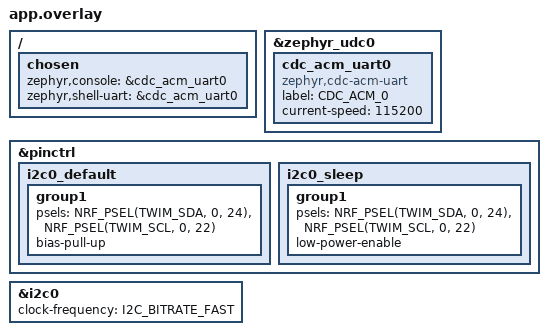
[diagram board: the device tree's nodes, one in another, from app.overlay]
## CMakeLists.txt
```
cmake_minimum_required(VERSION 3.20.0)

set(BOARD_ROOT ${CMAKE_SOURCE_DIR})
set(BOARD promicro_nrf52840/nrf52840)
set(DTC_OVERLAY_FILE "${CMAKE_SOURCE_DIR}/app.overlay")

find_package(Zephyr REQUIRED HINTS $ENV{ZEPHYR_BASE})
project(hello_world)

target_sources(app PRIVATE
    src/main.c
    src/transport.c
    src/ble.c
    src/imu.c
    src/gy85.c
)

target_include_directories(app PRIVATE src)
```

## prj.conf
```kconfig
CONFIG_USB_DEVICE_STACK=y
CONFIG_USB_DEVICE_PRODUCT="Hello World"
CONFIG_USB_DEVICE_PID=0x0001
CONFIG_USB_CDC_ACM=y
CONFIG_UART_INTERRUPT_DRIVEN=y
CONFIG_UART_LINE_CTRL=y
CONFIG_SERIAL=y
CONFIG_CONSOLE=y
CONFIG_UART_CONSOLE=y
CONFIG_USB_DEVICE_INITIALIZE_AT_BOOT=n
CONFIG_BUILD_OUTPUT_UF2=y
CONFIG_SHELL=y
CONFIG_KERNEL_SHELL=y
CONFIG_SHELL_BACKEND_SERIAL=y
CONFIG_REBOOT=y
CONFIG_CBPRINTF_FP_SUPPORT=y

CONFIG_I2C=y

# BLE
CONFIG_BT=y
CONFIG_BT_PERIPHERAL=y
CONFIG_BT_DEVICE_NAME="CR_IMU_BLE"
CONFIG_BT_DEVICE_APPEARANCE=0
CONFIG_BT_MAX_CONN=1
CONFIG_BT_GATT_DYNAMIC_DB=n

# MTU >= 39 for 36-byte payload; ACL TX buffers sized accordingly
CONFIG_BT_GATT_CLIENT=y
CONFIG_BT_L2CAP_TX_MTU=64
CONFIG_BT_BUF_ACL_TX_SIZE=72
CONFIG_BT_BUF_ACL_TX_COUNT=6
```

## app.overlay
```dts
/* ICM-45686 I2C mode. Wiring: DTQSYS SCL→P0.22, SDA→P0.24
 * QMC6309: via ICM-45686 internal I2C master (MREG over I2C)
 */

/ {
	chosen {
		zephyr,console = &cdc_acm_uart0;
		zephyr,shell-uart = &cdc_acm_uart0;
	};
};

&zephyr_udc0 {
	cdc_acm_uart0: cdc_acm_uart0 {
		compatible = "zephyr,cdc-acm-uart";
		label = "CDC_ACM_0";
		current-speed = <115200>;
	};
};

/* I2C0 pins with internal pull-ups for reliability */
&pinctrl {
	i2c0_default: i2c0_default {
		group1 {
			psels = <NRF_PSEL(TWIM_SDA, 0, 24)>,
					<NRF_PSEL(TWIM_SCL, 0, 22)>;
			bias-pull-up;
		};
	};
	i2c0_sleep: i2c0_sleep {
		group1 {
			psels = <NRF_PSEL(TWIM_SDA, 0, 24)>,
					<NRF_PSEL(TWIM_SCL, 0, 22)>;
			low-power-enable;
		};
	};
};

/* I2C0: TWIM, SDA=P0.24, SCL=P0.22, 400 kHz */
&i2c0 {
	status = "okay";
	clock-frequency = <I2C_BITRATE_FAST>;
};
```

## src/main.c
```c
#include <zephyr/kernel.h>
#include <zephyr/bluetooth/bluetooth.h>
#include <zephyr/bluetooth/gatt.h>
#include <zephyr/bluetooth/uuid.h>
#include <string.h>
#include "imu.h"
#include "transport.h"
#include "ble.h"

/* ── Частоты ─────────────────────────────────────────────────────────────── */
#define SAMPLE_HZ  100U   /* частота опроса датчика (должна совпадать с icm45686.c) */
#define BLE_HZ      25U   /* частота BLE-нотификаций                               */
#define LOG_HZ       1U   /* частота вывода в консоль (0 = выключить)              */

/*
 * GY-85 compatibility scaling — server pipeline expects ITG3200/ADXL345/HMC5883L counts:
 *   Gyro  (ITG3200):  14.375 LSB/°/s  → rad/s × (180/π) × 14.375 = × 823.4
 *   Accel (ADXL345):  256 LSB/g       → m/s² ÷ 9.81 × 256          = × 26.1
 *   Mag   (HMC5883L): 10.9 LSB/µT     → µT × 10.9
 *
 * Server pipeline: int16 / 100 / 0.14375 °/s → rad/s (gyro only; acc/mag are normalised).
 * 823.4 / 100 / 0.14375 × π/180 = 1.000 rad/s per rad/s ✓
 */
#define IMU_GYRO_SCALE   823.4f   /* rad/s  → ITG3200 counts */
#define IMU_ACCEL_SCALE   26.1f   /* m/s²   → ADXL345 counts */
#define IMU_MAG_SCALE     10.9f   /* µT     → HMC5883L counts */

/* IMU payload — 9 int16, 18 bytes. Fits in default ATT MTU=23 (max payload 20). */
typedef struct __attribute__((packed)) {
	int16_t gx, gy, gz;
	int16_t ax, ay, az;
	int16_t mx, my, mz;
} ImuPayload;

/* Service UUID:        eeb5483e-36e1-4688-b7f5-ea07361b26a8 */
/* Characteristic UUID: eeb5483e-36e1-4688-b7f5-ea07361b26a9 */
#define IMU_SVC_UUID_VAL \
	BT_UUID_128_ENCODE(0xeeb5483e, 0x36e1, 0x4688, 0xb7f5, 0xea07361b26a8)
#define IMU_CHR_UUID_VAL \
	BT_UUID_128_ENCODE(0xeeb5483e, 0x36e1, 0x4688, 0xb7f5, 0xea07361b26a9)

static struct bt_uuid_128 imu_svc_uuid = BT_UUID_INIT_128(IMU_SVC_UUID_VAL);
static struct bt_uuid_128 imu_chr_uuid = BT_UUID_INIT_128(IMU_CHR_UUID_VAL);

static ImuPayload imu_payload;

static void ccc_changed(const struct bt_gatt_attr *attr, uint16_t value)
{
	notify_enabled = (value == BT_GATT_CCC_NOTIFY);
	printk("Notify %s\n", notify_enabled ? "enabled" : "disabled");
}

BT_GATT_SERVICE_DEFINE(imu_svc,
	BT_GATT_PRIMARY_SERVICE(&imu_svc_uuid),
	BT_GATT_CHARACTERISTIC(&imu_chr_uuid.uuid,
		BT_GATT_CHRC_NOTIFY,
		BT_GATT_PERM_NONE,
		NULL, NULL, NULL),
	BT_GATT_CCC(ccc_changed, BT_GATT_PERM_READ | BT_GATT_PERM_WRITE),
);

static const struct bt_data ad[] = {
	BT_DATA_BYTES(BT_DATA_FLAGS, BT_LE_AD_GENERAL | BT_LE_AD_NO_BREDR),
	BT_DATA(BT_DATA_NAME_COMPLETE,
		CONFIG_BT_DEVICE_NAME,
		sizeof(CONFIG_BT_DEVICE_NAME) - 1),
};

static const struct bt_data sd[] = {
	BT_DATA_BYTES(BT_DATA_UUID128_ALL, IMU_SVC_UUID_VAL),
};

static void imu_log(const ImuPayload *data, uint32_t dt_us, uint32_t *cnt)
{
	if (LOG_HZ == 0 || ++(*cnt) < (SAMPLE_HZ / LOG_HZ)) {
		return;
	}
	*cnt = 0;
	uint32_t hz = (dt_us > 0) ? (1000000U / dt_us) : 0;
	printk("[dt=%uus ~%uHz] G:%.2f %.2f %.2f A:%.2f %.2f %.2f M:%.2f %.2f %.2f\n",
	       dt_us, hz,
	       (double)data->gx, (double)data->gy, (double)data->gz,
	       (double)data->ax, (double)data->ay, (double)data->az,
	       (double)data->mx, (double)data->my, (double)data->mz);
}

int main(void)
{
	int ret = transport_init();
	if (ret != 0) {
		while (1) { k_sleep(K_MSEC(1000)); }
	}

	ret = ble_init(ad, ARRAY_SIZE(ad), sd, ARRAY_SIZE(sd));
	if (ret != 0) {
		while (1) { k_sleep(K_MSEC(1000)); }
	}

	uint32_t log_cnt = 0;
	uint32_t notify_cnt = 0;
	uint32_t prev_ts_us = 0;

	while (1) {
		ImuData data;
		if (imu_get_data(&data)) {
			imu_payload.gx = (int16_t)(data.gx * IMU_GYRO_SCALE);
			imu_payload.gy = (int16_t)(data.gy * IMU_GYRO_SCALE);
			imu_payload.gz = (int16_t)(data.gz * IMU_GYRO_SCALE);
			imu_payload.ax = (int16_t)(data.ax * IMU_ACCEL_SCALE);
			imu_payload.ay = (int16_t)(data.ay * IMU_ACCEL_SCALE);
			imu_payload.az = (int16_t)(data.az * IMU_ACCEL_SCALE);
			imu_payload.mx = (int16_t)(data.mx * IMU_MAG_SCALE);
			imu_payload.my = (int16_t)(data.my * IMU_MAG_SCALE);
			imu_payload.mz = (int16_t)(data.mz * IMU_MAG_SCALE);

			uint32_t dt_us = (prev_ts_us != 0) ? (data.timestamp_us - prev_ts_us) : 0;
			prev_ts_us = data.timestamp_us;

			imu_log(&imu_payload, dt_us, &log_cnt);

			if (notify_enabled && (++notify_cnt % (SAMPLE_HZ / BLE_HZ)) == 0) {
				const struct bt_gatt_attr *attr = &imu_svc.attrs[2];
				bt_gatt_notify(current_conn, attr, &imu_payload, sizeof(imu_payload));
			}
		}
		k_sleep(K_MSEC(1000U / (SAMPLE_HZ * 5U)));
	}

	return 0;
}
```

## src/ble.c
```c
#include <zephyr/kernel.h>
#include <zephyr/bluetooth/bluetooth.h>
#include <zephyr/bluetooth/gatt.h>
#include "ble.h"

bool notify_enabled;
struct bt_conn *current_conn;

static const struct bt_data *adv_ad;
static size_t adv_ad_len;
static const struct bt_data *adv_sd;
static size_t adv_sd_len;

static struct k_work_delayable adv_work;
static struct k_work_delayable sub_watchdog;
static K_SEM_DEFINE(bt_ready_sem, 0, 1);

static void mtu_exchange_cb(struct bt_conn *conn, uint8_t err,
			     struct bt_gatt_exchange_params *params)
{
	printk("MTU exchange %s, MTU=%u\n",
	       err == 0 ? "OK" : "FAIL", bt_gatt_get_mtu(conn));
}
static struct bt_gatt_exchange_params mtu_params = { .func = mtu_exchange_cb };

static void adv_restart(void)
{
	bt_le_adv_stop();
	int ret = bt_le_adv_start(BT_LE_ADV_CONN, adv_ad, adv_ad_len, adv_sd, adv_sd_len);
	if (ret && ret != -EALREADY) {
		printk("BLE adv restart failed: %d, retrying...\n", ret);
		k_work_schedule(&adv_work, K_MSEC(500));
	} else {
		printk("BLE advertising restarted\n");
	}
}

static void adv_work_handler(struct k_work *work)
{
	adv_restart();
}

/* Periodic check: if connected but server is not subscribed to notifications,
 * the Python app likely died (BlueZ resets the CCC when the DBus owner dies).
 * Disconnect so advertising restarts and the new server session can connect. */
static void sub_watchdog_handler(struct k_work *work)
{
	if (!current_conn) {
		return;
	}
	if (!notify_enabled) {
		printk("BLE: no GATT subscription — dropping stale connection\n");
		bt_conn_disconnect(current_conn, BT_HCI_ERR_REMOTE_USER_TERM_CONN);
	} else {
		k_work_schedule(&sub_watchdog, K_SECONDS(5));
	}
}

static void adv_watchdog_thread(void *p1, void *p2, void *p3)
{
	k_sem_take(&bt_ready_sem, K_FOREVER);
	while (1) {
		k_sleep(K_SECONDS(3));
		if (current_conn != NULL) {
			continue;
		}
		printk("watchdog: forcing adv restart\n");
		adv_restart();
	}
}

K_THREAD_DEFINE(watchdog_tid, 1024, adv_watchdog_thread, NULL, NULL, NULL, 7, 0, 0);

static void connected(struct bt_conn *conn, uint8_t err)
{
	if (err) {
		printk("BLE connect failed: %d\n", err);
		return;
	}
	current_conn = bt_conn_ref(conn);
	printk("BLE connected, MTU=%u\n", bt_gatt_get_mtu(conn));

	k_work_schedule(&sub_watchdog, K_SECONDS(5));

	bt_gatt_exchange_mtu(conn, &mtu_params);

	/* 10–20 ms connection interval, 1 s supervision timeout */
	static const struct bt_le_conn_param param = {
		.interval_min = 8,   /* 8 × 1.25 ms = 10 ms */
		.interval_max = 16,  /* 16 × 1.25 ms = 20 ms */
		.latency = 0,
		.timeout = 100,      /* 100 × 10 ms = 1 s */
	};
	bt_conn_le_param_update(conn, &param);
}

static void disconnected(struct bt_conn *conn, uint8_t reason)
{
	printk("BLE disconnected: %d\n", reason);
	notify_enabled = false;
	k_work_cancel_delayable(&sub_watchdog);
	bt_conn_unref(current_conn);
	current_conn = NULL;
	k_work_schedule(&adv_work, K_MSEC(100));
}

BT_CONN_CB_DEFINE(conn_callbacks) = {
	.connected    = connected,
	.disconnected = disconnected,
};

int ble_init(const struct bt_data *ad, size_t ad_len,
             const struct bt_data *sd, size_t sd_len)
{
	adv_ad     = ad;
	adv_ad_len = ad_len;
	adv_sd     = sd;
	adv_sd_len = sd_len;

	k_work_init_delayable(&adv_work, adv_work_handler);
	k_work_init_delayable(&sub_watchdog, sub_watchdog_handler);

	int ret = bt_enable(NULL);
	if (ret != 0) {
		printk("BLE init failed: %d\n", ret);
		return ret;
	}

	ret = bt_le_adv_start(BT_LE_ADV_CONN, ad, ad_len, sd, sd_len);
	if (ret != 0) {
		printk("BLE adv failed: %d\n", ret);
		return ret;
	}

	printk("BLE advertising as \"%s\"\n", CONFIG_BT_DEVICE_NAME);
	k_sem_give(&bt_ready_sem);
	return 0;
}
```

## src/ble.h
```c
#ifndef BLE_H
#define BLE_H

#include <stdbool.h>
#include <zephyr/bluetooth/bluetooth.h>
#include <zephyr/bluetooth/conn.h>

extern bool notify_enabled;
extern struct bt_conn *current_conn;

int ble_init(const struct bt_data *ad, size_t ad_len,
             const struct bt_data *sd, size_t sd_len);

#endif /* BLE_H */
```

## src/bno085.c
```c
#include "bno085.h"
#include "bno085_hal.h"
#include "imu.h"
#include "imu_driver.h"
#include "sh2/sh2.h"
#include "sh2/sh2_SensorValue.h"
#include "sh2/sh2_err.h"
#include <zephyr/kernel.h>
#include <zephyr/init.h>
#include <string.h>

static ImuData latest;
static bool data_ready;
static K_MUTEX_DEFINE(bno085_mutex);

static void sensor_cb(void *cookie, sh2_SensorEvent_t *event)
{
	sh2_SensorValue_t val;
	if (sh2_decodeSensorEvent(&val, event) != SH2_OK) {
		return;
	}

	k_mutex_lock(&bno085_mutex, K_FOREVER);
	switch (val.sensorId) {
	case SH2_GYROSCOPE_CALIBRATED:
		latest.gx = val.un.gyroscope.x;
		latest.gy = val.un.gyroscope.y;
		latest.gz = val.un.gyroscope.z;
		break;
	case SH2_ACCELEROMETER:
		latest.ax = val.un.accelerometer.x;
		latest.ay = val.un.accelerometer.y;
		latest.az = val.un.accelerometer.z;
		latest.timestamp_us = (uint32_t)(k_uptime_get() * 1000U);
		data_ready = true;
		break;
	case SH2_MAGNETIC_FIELD_CALIBRATED:
		latest.mx = val.un.magneticField.x;
		latest.my = val.un.magneticField.y;
		latest.mz = val.un.magneticField.z;
		break;
	}
	k_mutex_unlock(&bno085_mutex);
}

static void configure_sensors(void)
{
	sh2_SensorConfig_t cfg = {0};
	cfg.reportInterval_us = 1000000U / IMU_SAMPLE_HZ;
	sh2_setSensorConfig(SH2_GYROSCOPE_CALIBRATED, &cfg);
	sh2_setSensorConfig(SH2_ACCELEROMETER,        &cfg);
	cfg.reportInterval_us = MAX(1000000U / IMU_SAMPLE_HZ, 10000U);
	sh2_setSensorConfig(SH2_MAGNETIC_FIELD_CALIBRATED, &cfg);
	printk("BNO085: gyro/accel %uHz, mag %uHz\n",
	       IMU_SAMPLE_HZ, 1000000U / cfg.reportInterval_us);
}

static void event_cb(void *cookie, sh2_AsyncEvent_t *event)
{
	if (event->eventId == SH2_RESET) {
		printk("BNO085: reset — reconfiguring sensors\n");
		configure_sensors();
	}
}

static void bno085_thread(void *p1, void *p2, void *p3)
{
	k_sleep(K_SECONDS(5));
	printk("BNO085: thread started, opening...\n");
	int ret = sh2_open(&bno085_hal, event_cb, NULL);
	if (ret != SH2_OK) {
		printk("BNO085: sh2_open failed: %d\n", ret);
		return;
	}
	printk("BNO085: sh2_open OK\n");

	sh2_setSensorCallback(sensor_cb, NULL);

	k_sleep(K_MSEC(100));

	configure_sensors();

	while (1) {
		sh2_service();
		k_yield();
	}
}

K_THREAD_DEFINE(bno085_tid, 4096, bno085_thread, NULL, NULL, NULL, 5, 0, 0);

static bool bno085_get_data(ImuData *out)
{
	k_mutex_lock(&bno085_mutex, K_FOREVER);
	bool ready = data_ready;
	if (ready) {
		*out = latest;
		data_ready = false;
	}
	k_mutex_unlock(&bno085_mutex);
	return ready;
}

static const ImuDriverOps bno085_driver = {
	.init     = NULL,
	.get_data = bno085_get_data,
};

static int bno085_register(void)
{
	imu_register_driver(&bno085_driver);
	return 0;
}

SYS_INIT(bno085_register, APPLICATION, CONFIG_APPLICATION_INIT_PRIORITY);
```

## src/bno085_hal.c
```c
#include "bno085_hal.h"
#include <zephyr/kernel.h>
#include <zephyr/drivers/i2c.h>
#include <string.h>

#define BNO085_ADDR 0x4B

static const struct device *i2c_dev;

static int bno_open(sh2_Hal_t *self)
{
    i2c_dev = DEVICE_DT_GET(DT_NODELABEL(i2c0));
    if (!device_is_ready(i2c_dev)) {
        printk("BNO085: i2c0 not ready\n");
        return -1;
    }

    k_sleep(K_MSEC(300));
    return 0;
}

static void bno_close(sh2_Hal_t *self)
{
    i2c_dev = NULL;
}

static int bno_read(sh2_Hal_t *self, uint8_t *pBuffer, unsigned len, uint32_t *t_us)
{
    /* First read: 4-byte header to get packet length */
    uint8_t hdr[4];
    if (i2c_read(i2c_dev, hdr, sizeof(hdr), BNO085_ADDR) != 0) {
        return 0;
    }

    uint16_t pkt_len = ((uint16_t)hdr[1] << 8) | hdr[0];
    pkt_len &= 0x7FFF; /* strip continuation bit */

    if (pkt_len < 4 || pkt_len > len) {
        return 0;
    }

    /* Second read: BNO085 resets its pointer at each I2C START condition,
     * so we must read the full packet (header + payload) from the beginning */
    if (i2c_read(i2c_dev, pBuffer, pkt_len, BNO085_ADDR) != 0) {
        return 0;
    }

    *t_us = (uint32_t)(k_uptime_get() * 1000U);
    return pkt_len;
}

static int bno_write(sh2_Hal_t *self, uint8_t *pBuffer, unsigned len)
{
    int ret = i2c_write(i2c_dev, pBuffer, len, BNO085_ADDR);
    if (ret != 0) {
        return -1; /* SHTP: -1 = abort, 0 = retry, >0 = success */
    }
    return len;
}

static uint32_t bno_get_time_us(sh2_Hal_t *self)
{
    return (uint32_t)(k_uptime_get() * 1000U);
}

sh2_Hal_t bno085_hal = {
    .open      = bno_open,
    .close     = bno_close,
    .read      = bno_read,
    .write     = bno_write,
    .getTimeUs = bno_get_time_us,
};
```

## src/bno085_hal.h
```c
#pragma once
#include "sh2/sh2_hal.h"

extern sh2_Hal_t bno085_hal;
```

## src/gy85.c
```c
#include "imu.h"
#include "imu_driver.h"

#include <zephyr/kernel.h>
#include <zephyr/init.h>
#include <zephyr/drivers/i2c.h>
#include <zephyr/sys/printk.h>
#include <stdbool.h>
#include <stdint.h>
#include <stdlib.h>

/* ── ITG3200 gyroscope ───────────────────────────────────────────────────── */
#define ITG_ADDR       0x68u
#define ITG_WHO_AM_I   0x00u
#define ITG_SMPLRT_DIV 0x15u
#define ITG_DLPF_FS    0x16u
#define ITG_PWR_MGM    0x3Eu
#define ITG_TEMP_H     0x1Bu  /* TEMP_H TEMP_L GX_H GX_L GY_H GY_L GZ_H GZ_L */
/* FS_SEL=3 → 14.375 LSB/°/s; to rad/s: raw × π/(14.375×180) */
#define ITG_SCALE      (3.14159265f / (14.375f * 180.0f))

/* ── ADXL345 accelerometer ───────────────────────────────────────────────── */
#define ADXL_ADDR      0x53u  /* SDO=GND on standard GY-85; use 0x1D if SDO=3V3 */
#define ADXL_DEVID     0x00u
#define ADXL_BW_RATE   0x2Cu
#define ADXL_PWR_CTL   0x2Du
#define ADXL_FORMAT    0x31u
#define ADXL_DATAX0    0x32u
/* ±2g, 256 LSB/g; to m/s²: raw × 9.81/256 */
#define ADXL_SCALE     (9.81f / 256.0f)

/* ── HMC5883L magnetometer ───────────────────────────────────────────────── */
#define HMC_ADDR       0x1Eu
#define HMC_CFG_A      0x00u
#define HMC_CFG_B      0x01u
#define HMC_MODE       0x02u
#define HMC_DATA_H     0x03u  /* X_H X_L Z_H Z_L Y_H Y_L (Z before Y!) */
#define HMC_STATUS     0x09u
#define HMC_IDA        0x0Au  /* 'H' = 0x48 */
/* gain=1 (Config B=0x20) → 1090 LSB/Ga = 10.9 LSB/µT; to µT: raw/10.9 */
#define HMC_SCALE      (1.0f / 10.9f)
#define HMC_POLL_MS    14u    /* 75 Hz output → poll every ~13 ms */

static const struct device *i2c_dev;

static inline int rd(uint8_t addr, uint8_t reg, uint8_t *buf, uint8_t len)
{
	return i2c_burst_read(i2c_dev, addr, reg, buf, len);
}

static inline int wr(uint8_t addr, uint8_t reg, uint8_t val)
{
	return i2c_reg_write_byte(i2c_dev, addr, reg, val);
}

/* ── ITG3200 ─────────────────────────────────────────────────────────────── */
static bool itg3200_init(void)
{
	uint8_t id = 0;
	if (rd(ITG_ADDR, ITG_WHO_AM_I, &id, 1) != 0) {
		printk("ITG3200: no ACK at 0x%02X\n", ITG_ADDR);
		return false;
	}
	/* WHO_AM_I bits[6:1] = fixed 110100; bit0 = AD0. Expect 0x68 or 0x69 */
	if (id != 0x68 && id != 0x69) {
		printk("ITG3200 WHO_AM_I=0x%02X unexpected\n", id);
		return false;
	}
	printk("ITG3200 WHO_AM_I=0x%02X OK\n", id);

	wr(ITG_ADDR, ITG_PWR_MGM, 0x80);  /* reset */
	k_sleep(K_MSEC(10));
	wr(ITG_ADDR, ITG_DLPF_FS, 0x19);  /* FS_SEL=3 (±2000°/s), DLPF=1 (188Hz BW) */
	wr(ITG_ADDR, ITG_SMPLRT_DIV, 9);  /* 1kHz / 10 = 100Hz sample rate */
	wr(ITG_ADDR, ITG_PWR_MGM, 0x01);  /* PLL with X gyro clock */
	k_sleep(K_MSEC(50));
	return true;
}

static bool itg3200_read(float *gx, float *gy, float *gz)
{
	uint8_t buf[8];
	if (rd(ITG_ADDR, ITG_TEMP_H, buf, 8) != 0) return false;
	/* big-endian: [TEMP_H TEMP_L GX_H GX_L GY_H GY_L GZ_H GZ_L] */
	int16_t rx = (int16_t)((buf[2] << 8) | buf[3]);
	int16_t ry = (int16_t)((buf[4] << 8) | buf[5]);
	int16_t rz = (int16_t)((buf[6] << 8) | buf[7]);
	*gx = rx * ITG_SCALE;
	*gy = ry * ITG_SCALE;
	*gz = rz * ITG_SCALE;
	return true;
}

/* ── ADXL345 ─────────────────────────────────────────────────────────────── */
static bool adxl345_init(void)
{
	uint8_t id = 0;
	if (rd(ADXL_ADDR, ADXL_DEVID, &id, 1) != 0) {
		printk("ADXL345: no ACK at 0x%02X\n", ADXL_ADDR);
		return false;
	}
	if (id != 0xE5) {
		printk("ADXL345 DEVID=0x%02X unexpected (expect 0xE5)\n", id);
		return false;
	}
	printk("ADXL345 DEVID=0xE5 OK\n");

	wr(ADXL_ADDR, ADXL_FORMAT,  0x00);  /* ±2g, right-justified 10-bit */
	wr(ADXL_ADDR, ADXL_BW_RATE, 0x0A); /* 100Hz output */
	wr(ADXL_ADDR, ADXL_PWR_CTL, 0x08); /* measure mode */
	k_sleep(K_MSEC(10));
	return true;
}

static bool adxl345_read(float *ax, float *ay, float *az)
{
	uint8_t buf[6];
	if (rd(ADXL_ADDR, ADXL_DATAX0, buf, 6) != 0) return false;
	/* little-endian: [X0 X1 Y0 Y1 Z0 Z1] */
	int16_t rx = (int16_t)((buf[1] << 8) | buf[0]);
	int16_t ry = (int16_t)((buf[3] << 8) | buf[2]);
	int16_t rz = (int16_t)((buf[5] << 8) | buf[4]);
	*ax = rx * ADXL_SCALE;
	*ay = ry * ADXL_SCALE;
	*az = rz * ADXL_SCALE;
	return true;
}

/* ── HMC5883L ────────────────────────────────────────────────────────────── */
static float hmc_last[3] = {0};
static uint32_t hmc_next_ms = 0;

static bool hmc5883l_init(void)
{
	uint8_t id = 0;
	if (rd(HMC_ADDR, HMC_IDA, &id, 1) != 0) {
		printk("HMC5883L: no ACK at 0x%02X\n", HMC_ADDR);
		return false;
	}
	if (id != 0x48) {  /* 'H' */
		printk("HMC5883L IDA=0x%02X unexpected (expect 0x48)\n", id);
		return false;
	}
	printk("HMC5883L IDA=0x48 OK\n");

	wr(HMC_ADDR, HMC_CFG_A, 0x18);  /* 1-sample avg, 75Hz output rate */
	wr(HMC_ADDR, HMC_CFG_B, 0x20);  /* gain=1: ±1.3 Ga, 1090 LSB/Ga */
	wr(HMC_ADDR, HMC_MODE,  0x00);  /* continuous measurement mode */
	k_sleep(K_MSEC(10));
	return true;
}

static void hmc5883l_update(float *mx, float *my, float *mz)
{
	uint32_t now = k_uptime_get_32();
	if ((int32_t)(now - hmc_next_ms) < 0) {
		*mx = hmc_last[0]; *my = hmc_last[1]; *mz = hmc_last[2];
		return;
	}
	hmc_next_ms = now + HMC_POLL_MS;

	uint8_t st = 0;
	if (rd(HMC_ADDR, HMC_STATUS, &st, 1) != 0 || !(st & 0x01)) {
		*mx = hmc_last[0]; *my = hmc_last[1]; *mz = hmc_last[2];
		return;
	}

	uint8_t buf[6];
	if (rd(HMC_ADDR, HMC_DATA_H, buf, 6) != 0) {
		*mx = hmc_last[0]; *my = hmc_last[1]; *mz = hmc_last[2];
		return;
	}

	/* big-endian: [X_H X_L Z_H Z_L Y_H Y_L] — Z before Y is correct per datasheet */
	int16_t rx = (int16_t)((buf[0] << 8) | buf[1]);
	int16_t rz = (int16_t)((buf[2] << 8) | buf[3]);
	int16_t ry = (int16_t)((buf[4] << 8) | buf[5]);

	/* ±4096 = overflow sentinel */
	if (rx == -4096 || ry == -4096 || rz == -4096) {
		*mx = hmc_last[0]; *my = hmc_last[1]; *mz = hmc_last[2];
		return;
	}

	hmc_last[0] = rx * HMC_SCALE;
	hmc_last[1] = ry * HMC_SCALE;
	hmc_last[2] = rz * HMC_SCALE;
	*mx = hmc_last[0]; *my = hmc_last[1]; *mz = hmc_last[2];
}

/* ── Sensor thread ───────────────────────────────────────────────────────── */
static ImuData latest = {0};
static bool data_ready = false;
static K_MUTEX_DEFINE(gy85_mutex);

static void gy85_thread(void *p1, void *p2, void *p3)
{
	ARG_UNUSED(p1); ARG_UNUSED(p2); ARG_UNUSED(p3);

	k_sleep(K_MSEC(4000));

	i2c_dev = DEVICE_DT_GET(DT_NODELABEL(i2c0));
	if (!device_is_ready(i2c_dev)) {
		printk("I2C0 not ready! Check app.overlay\n");
		return;
	}

	bool itg_ok = false, adxl_ok = false, hmc_ok = false;
	for (int attempt = 1; !(itg_ok && adxl_ok); attempt++) {
		itg_ok  = itg3200_init();
		adxl_ok = adxl345_init();
		if (!(itg_ok && adxl_ok)) {
			printk("GY-85 init fail (attempt %d), retry in 2s\n", attempt);
			k_sleep(K_MSEC(2000));
		}
	}
	hmc_ok = hmc5883l_init();
	printk("GY-85 ready: ITG=%d ADXL=%d HMC=%d\n", itg_ok, adxl_ok, hmc_ok);

	int64_t next_tick = k_uptime_get() + 10;

	while (1) {
		float gx, gy, gz, ax, ay, az, mx = 0, my = 0, mz = 0;

		bool ok = itg3200_read(&gx, &gy, &gz) && adxl345_read(&ax, &ay, &az);
		if (hmc_ok) hmc5883l_update(&mx, &my, &mz);

		if (ok) {
			k_mutex_lock(&gy85_mutex, K_FOREVER);
			latest.gx = gx; latest.gy = gy; latest.gz = gz;
			latest.ax = ax; latest.ay = ay; latest.az = az;
			latest.mx = mx; latest.my = my; latest.mz = mz;
			latest.timestamp_us = (uint32_t)(k_uptime_get() * 1000U);
			data_ready = true;
			k_mutex_unlock(&gy85_mutex);
		}

		int64_t delay = next_tick - k_uptime_get();
		if (delay > 0) k_sleep(K_MSEC((int32_t)delay));
		next_tick += 10;
	}
}

K_THREAD_DEFINE(gy85_tid, 2048, gy85_thread, NULL, NULL, NULL, 5, 0, 0);

/* ── IMU driver registration ─────────────────────────────────────────────── */
static bool gy85_get_data(ImuData *out)
{
	k_mutex_lock(&gy85_mutex, K_FOREVER);
	bool ready = data_ready;
	if (ready) {
		*out = latest;
		data_ready = false;
	}
	k_mutex_unlock(&gy85_mutex);
	return ready;
}

static const ImuDriverOps gy85_driver = {
	.init     = NULL,
	.get_data = gy85_get_data,
};

static int gy85_register(void)
{
	imu_register_driver(&gy85_driver);
	return 0;
}

SYS_INIT(gy85_register, APPLICATION, CONFIG_APPLICATION_INIT_PRIORITY);
```

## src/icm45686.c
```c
#include "imu.h"
#include "imu_driver.h"

#include <zephyr/kernel.h>
#include <zephyr/init.h>
#include <zephyr/drivers/i2c.h>
#include <zephyr/sys/printk.h>
#include <zephyr/sys/util.h>

#include <string.h>
#include <errno.h>
#include <stdbool.h>
#include <stdint.h>
#include <stdlib.h>
#include <math.h>

/* ==================== ICM-45686 registers ==================== */
#define ICM_REG_ACCEL_X0     0x00
#define ICM_REG_PWR_MGMT0    0x10
#define ICM_REG_ACCEL_CFG0   0x1B
#define ICM_REG_GYRO_CFG0    0x1C
#define ICM_REG_WHO_AM_I     0x72
#define ICM_WHO_AM_I_VAL     0xE9

#define ICM_PWR_LN           0x0F
/* ICM-45686 FS_SEL bits are at [7:4], ODR at [3:0].
 * ACCEL_CONFIG0: 0000=±32g 0001=±16g 0010=±8g 0011=±4g 0100=±2g
 * GYRO_CONFIG0:  0000=±4000dps 0001=±2000dps 0010=±1000dps ... */
#define ICM_ACCEL_CFG_VAL    (0x40 | 0x09)   /* bits[7:4]=0100 → ±2g,     ODR=200 Hz */
#define ICM_GYRO_CFG_VAL     (0x10 | 0x09)   /* bits[7:4]=0001 → ±2000dps, ODR=200 Hz */

#define ICM_ACCEL_SCALE      (2.0f * 9.81f / 32768.0f)   /* ±2g */
#define ICM_GYRO_SCALE       (2000.0f * 3.14159265f / (180.0f * 32768.0f))   /* ±2000dps */

/* I2C addresses: AP_AD0=0 → 0x68, AP_AD0=1 → 0x69 */
#define ICM_ADDR_0           0x68u
#define ICM_ADDR_1           0x69u

/* MREG (indirect register) access */
#define ICM_IREG_ADDR_H      0x7Cu
#define ICM_IREG_DATA        0x7Eu

static const struct device *i2c_dev;
static uint8_t icm_addr;
static K_MUTEX_DEFINE(icm_bus_mutex);

/* Gyro zero-rate offset measured at startup (rad/s). */
static float gyro_bias[3] = {0};

/* ==================== I2C low-level ==================== */
static int icm_read(uint8_t reg, uint8_t *buf, uint8_t len)
{
	return i2c_burst_read(i2c_dev, icm_addr, reg, buf, len);
}

static int icm_write(uint8_t reg, uint8_t val)
{
	return i2c_reg_write_byte(i2c_dev, icm_addr, reg, val);
}

/* ==================== MREG (indirect) access ==================== */
/* Writes addr_h, addr_l, val to IREG_ADDR_H/L/DATA in one burst */
static int icm_mreg_write_nolock(uint16_t addr, uint8_t val)
{
	uint8_t tx[3] = { addr >> 8, addr & 0xFF, val };
	return i2c_burst_write(i2c_dev, icm_addr, ICM_IREG_ADDR_H, tx, 3);
}

/* Sets IREG address, waits briefly, reads IREG_DATA */
static int icm_mreg_read_nolock(uint16_t addr, uint8_t *val)
{
	uint8_t tx[2] = { addr >> 8, addr & 0xFF };
	int rc = i2c_burst_write(i2c_dev, icm_addr, ICM_IREG_ADDR_H, tx, 2);
	if (rc) return rc;
	k_busy_wait(50);
	return i2c_reg_read_byte(i2c_dev, icm_addr, ICM_IREG_DATA, val);
}

/* ==================== I2CM master registers ==================== */
#define I2CM_COMMAND_0       0xa206u
#define I2CM_DEV_PROFILE0    0xa20eu
#define I2CM_DEV_PROFILE1    0xa20fu
#define I2CM_CONTROL         0xa216u
#define I2CM_STATUS          0xa218u
#define I2CM_EXT_DEV_STATUS  0xa21au
#define I2CM_RD_DATA0        0xa21bu
#define I2CM_WR_DATA0        0xa233u

#define I2CM_CTRL_WRITE      (0x08u | 0x01u)
#define I2CM_CTRL_READ       (0x40u | 0x08u | 0x01u)

static void icm_i2cm_reset_nolock(void)
{
	uint8_t dummy;
	icm_mreg_read_nolock(I2CM_STATUS, &dummy);
	icm_mreg_read_nolock(I2CM_EXT_DEV_STATUS, &dummy);
}

static int icm_i2cm_wait_nolock(void)
{
	uint8_t st = 0;
	for (int i = 0; i < 18; i++) {
		if (icm_mreg_read_nolock(I2CM_STATUS, &st) != 0) return -EIO;
		if ((st & 0x02) && !(st & 0x01)) {
			return (st & 0x3C) ? -EIO : 0;
		}
		k_busy_wait(100);
	}
	return -ETIMEDOUT;
}

static int icm_i2cm_read_reg(uint8_t addr, uint8_t reg, uint8_t *val)
{
	k_mutex_lock(&icm_bus_mutex, K_FOREVER);
	icm_i2cm_reset_nolock();
	int rc = 0;
	rc |= icm_mreg_write_nolock(I2CM_DEV_PROFILE0, reg);
	rc |= icm_mreg_write_nolock(I2CM_DEV_PROFILE1, addr);
	rc |= icm_mreg_write_nolock(I2CM_COMMAND_0, 0x91);
	rc |= icm_mreg_write_nolock(I2CM_CONTROL, I2CM_CTRL_READ);
	if (rc == 0 && icm_i2cm_wait_nolock() == 0) {
		uint8_t dev_st;
		icm_mreg_read_nolock(I2CM_EXT_DEV_STATUS, &dev_st);
		if (!(dev_st & 0x01))
			rc = icm_mreg_read_nolock(I2CM_RD_DATA0, val);
		else
			rc = -EIO;
	}
	k_mutex_unlock(&icm_bus_mutex);
	return rc;
}

static int icm_i2cm_read_bytes(uint8_t addr, uint8_t reg, uint8_t *buf, uint8_t len)
{
	if (len == 0 || len > 15) return -EINVAL;
	k_mutex_lock(&icm_bus_mutex, K_FOREVER);
	icm_i2cm_reset_nolock();
	int rc = 0;
	rc |= icm_mreg_write_nolock(I2CM_DEV_PROFILE0, reg);
	rc |= icm_mreg_write_nolock(I2CM_DEV_PROFILE1, addr);
	rc |= icm_mreg_write_nolock(I2CM_COMMAND_0, 0x90 | (len & 0x0F));
	rc |= icm_mreg_write_nolock(I2CM_CONTROL, I2CM_CTRL_READ);
	if (rc == 0 && icm_i2cm_wait_nolock() == 0) {
		uint8_t dev_st;
		icm_mreg_read_nolock(I2CM_EXT_DEV_STATUS, &dev_st);
		if (!(dev_st & 0x01)) {
			for (int i = 0; i < len; i++) {
				if (icm_mreg_read_nolock(I2CM_RD_DATA0 + i, &buf[i]) != 0) {
					rc = -EIO;
					break;
				}
			}
		} else rc = -EIO;
	}
	k_mutex_unlock(&icm_bus_mutex);
	return rc;
}

static int icm_i2cm_write_reg(uint8_t addr, uint8_t reg, uint8_t val)
{
	k_mutex_lock(&icm_bus_mutex, K_FOREVER);
	icm_i2cm_reset_nolock();
	int rc = 0;
	rc |= icm_mreg_write_nolock(I2CM_DEV_PROFILE1, addr);
	rc |= icm_mreg_write_nolock(I2CM_WR_DATA0, reg);
	rc |= icm_mreg_write_nolock(I2CM_WR_DATA0 + 1, val);
	rc |= icm_mreg_write_nolock(I2CM_COMMAND_0, 0x82);
	rc |= icm_mreg_write_nolock(I2CM_CONTROL, I2CM_CTRL_WRITE);
	if (rc == 0) icm_i2cm_wait_nolock();
	k_mutex_unlock(&icm_bus_mutex);
	return rc;
}

/* ==================== ICM-45686 sensor configuration ==================== */
static void icm45686_configure(void)
{
	icm_write(ICM_REG_PWR_MGMT0, 0x00);
	k_sleep(K_MSEC(2));
	icm_write(ICM_REG_ACCEL_CFG0, ICM_ACCEL_CFG_VAL);
	icm_write(ICM_REG_GYRO_CFG0,  ICM_GYRO_CFG_VAL);
	icm_write(ICM_REG_PWR_MGMT0,  ICM_PWR_LN);
	k_sleep(K_MSEC(50));

	/* Enable ICM internal I2C master for QMC6309 */
	uint8_t tmp;
	icm_read(0x2F, &tmp, 1); tmp = (tmp & ~0x07u) | 0x03u; icm_write(0x2F, tmp);
	icm_read(0x30, &tmp, 1); tmp = (tmp & ~0x1Fu) | 0x17u; icm_write(0x30, tmp);
	k_sleep(K_MSEC(5));
}

/* ==================== ICM-45686 initialisation ==================== */
static bool icm45686_init(void)
{
	/* Try both I2C addresses */
	static const uint8_t addrs[] = { ICM_ADDR_0, ICM_ADDR_1 };
	for (int i = 0; i < 2; i++) {
		icm_addr = addrs[i];
		uint8_t who = 0;
		int rc = icm_read(ICM_REG_WHO_AM_I, &who, 1);
		printk("ICM @ 0x%02X  WHO_AM_I=0x%02X  rc=%d\n", icm_addr, who, rc);
		if (rc == 0 && who == ICM_WHO_AM_I_VAL) {
			printk("ICM found at 0x%02X\n", icm_addr);
			/* Soft reset then configure */
			icm_write(0x01, 0x01);
			k_sleep(K_MSEC(12));
			icm45686_configure();
			printk("ICM OK\n");
			return true;
		}
	}
	printk("ICM FAIL: не найден на 0x68 и 0x69. Проверь:\n"
	       "  DTQSYS SDA → P0.24,  SCL → P0.22\n"
	       "  Питание 3V3 и GND подключены\n");
	return false;
}

/* ==================== ICM read with validation ==================== */
static bool icm45686_read_valid(ImuData *d)
{
	static int bad_frames = 0;
	static uint32_t last_reset_ms = 0;

	for (int attempt = 0; attempt < 3; attempt++) {
		uint8_t buf[12];
		if (icm_read(ICM_REG_ACCEL_X0, buf, 12) != 0) continue;

		int16_t ax = (int16_t)((buf[1]<<8)|buf[0]);
		int16_t ay = (int16_t)((buf[3]<<8)|buf[2]);
		int16_t az = (int16_t)((buf[5]<<8)|buf[4]);
		int16_t gx = (int16_t)((buf[7]<<8)|buf[6]);
		int16_t gy = (int16_t)((buf[9]<<8)|buf[8]);
		int16_t gz = (int16_t)((buf[11]<<8)|buf[10]);

		int64_t anorm2 = (int64_t)ax*ax + (int64_t)ay*ay + (int64_t)az*az;
		if (anorm2 < 25000000LL) {
			if (bad_frames == 0) {
				printk("ICM bad frame raw: %02x %02x %02x %02x %02x %02x "
				       "%02x %02x %02x %02x %02x %02x  ax=%d ay=%d az=%d\n",
				       buf[0],buf[1],buf[2],buf[3],buf[4],buf[5],
				       buf[6],buf[7],buf[8],buf[9],buf[10],buf[11],
				       ax, ay, az);
			}
			bad_frames++;
			if (bad_frames >= 4) {
				uint32_t now = k_uptime_get_32();
				if (now - last_reset_ms > 1500) {
					printk("ICM bad frames, soft reset\n");
					icm_write(0x01, 0x01);
					k_sleep(K_MSEC(12));
					icm45686_configure();
					last_reset_ms = now;
				}
				bad_frames = 0;
			}
			continue;
		}

		if (abs(gx) > 29000 || abs(gy) > 29000 || abs(gz) > 29000) {
			bad_frames++;
			continue;
		}

		bad_frames = 0;
		d->ax = ax * ICM_ACCEL_SCALE;
		d->ay = ay * ICM_ACCEL_SCALE;
		d->az = az * ICM_ACCEL_SCALE;
		d->gx = gx * ICM_GYRO_SCALE - gyro_bias[0];
		d->gy = gy * ICM_GYRO_SCALE - gyro_bias[1];
		d->gz = gz * ICM_GYRO_SCALE - gyro_bias[2];
		d->timestamp_us = (uint32_t)(k_uptime_get() * 1000U);
		return true;
	}
	return false;
}

/* ==================== QMC6309 via I2CM ==================== */
#define QMC_ADDR_7BIT     0x7Cu
#define QMC_REG_CHIP_ID   0x00
#define QMC_REG_DATA_X0   0x01
#define QMC_REG_STATUS    0x09
#define QMC_REG_CTRL1     0x0A
#define QMC_REG_CTRL2     0x0B
#define QMC_CHIP_ID_VAL   0x90
#define QMC_CTRL1_CONT    0x63
#define QMC_CTRL2_RESET   0x80
#define QMC_CTRL2_CLEAR   0x00

#define QMC_MAG_SCALE        0.1f
#define QMC_READ_INTERVAL_MS 30u

static bool qmc_has_last = false;
static uint32_t qmc_next_poll_ms = 0;
static int16_t qmc_last_raw[3] = {0};
static float qmc_last[3] = {0};

static bool qmc6309_init(void)
{
	uint8_t id = 0;
	if (icm_i2cm_read_reg(QMC_ADDR_7BIT, QMC_REG_CHIP_ID, &id) != 0) {
		printk("QMC6309: no ACK\n");
		return false;
	}
	printk("QMC6309 CHIP_ID = 0x%02X\n", id);

	icm_i2cm_write_reg(QMC_ADDR_7BIT, QMC_REG_CTRL2, QMC_CTRL2_RESET);
	k_sleep(K_MSEC(10));
	icm_i2cm_write_reg(QMC_ADDR_7BIT, QMC_REG_CTRL2, QMC_CTRL2_CLEAR);
	k_sleep(K_MSEC(5));
	icm_i2cm_write_reg(QMC_ADDR_7BIT, QMC_REG_CTRL1, QMC_CTRL1_CONT);
	k_sleep(K_MSEC(10));

	printk("QMC6309 ready\n");
	return true;
}

static void qmc6309_update(ImuData *d)
{
	uint32_t now = k_uptime_get_32();

	if (qmc_has_last && (int32_t)(now - qmc_next_poll_ms) < 0) {
		d->mx = qmc_last[0]; d->my = qmc_last[1]; d->mz = qmc_last[2];
		return;
	}
	qmc_next_poll_ms = now + QMC_READ_INTERVAL_MS;

	uint8_t st = 0;
	if (icm_i2cm_read_reg(QMC_ADDR_7BIT, QMC_REG_STATUS, &st) != 0 ||
	    (st & 0x01) == 0 || (st & 0x02) != 0) {
		d->mx = qmc_last[0]; d->my = qmc_last[1]; d->mz = qmc_last[2];
		return;
	}

	uint8_t buf[6];
	if (icm_i2cm_read_bytes(QMC_ADDR_7BIT, QMC_REG_DATA_X0, buf, 6) != 0) {
		d->mx = qmc_last[0]; d->my = qmc_last[1]; d->mz = qmc_last[2];
		return;
	}

	int16_t raw[3] = {
		(int16_t)((buf[1]<<8)|buf[0]),
		(int16_t)((buf[3]<<8)|buf[2]),
		(int16_t)((buf[5]<<8)|buf[4])
	};

	float norm = sqrtf((float)(raw[0]*raw[0] + raw[1]*raw[1] + raw[2]*raw[2]));
	if (norm < 140.0f || norm > 1300.0f) {
		d->mx = qmc_last[0]; d->my = qmc_last[1]; d->mz = qmc_last[2];
		return;
	}

	if (qmc_has_last) {
		if (abs(raw[0] - qmc_last_raw[0]) > 4000 ||
		    abs(raw[1] - qmc_last_raw[1]) > 4000 ||
		    abs(raw[2] - qmc_last_raw[2]) > 4000) {
			d->mx = qmc_last[0]; d->my = qmc_last[1]; d->mz = qmc_last[2];
			return;
		}
	}

	qmc_last_raw[0] = raw[0]; qmc_last_raw[1] = raw[1]; qmc_last_raw[2] = raw[2];
	qmc_has_last = true;

	/* Output raw QMC µT values — axis alignment is handled by the server-side
	 * mag_cal joint calibration (mag + gravity ellipsoid fit). Any fixed
	 * firmware rotation would need to be reapplied after every recalibration
	 * and is redundant when mag_cal can absorb it automatically. */
	float nv[3] = {
		raw[0] * QMC_MAG_SCALE,
		raw[1] * QMC_MAG_SCALE,
		raw[2] * QMC_MAG_SCALE,
	};

	const float alpha = 0.5f;
	if (qmc_last[0] == 0.0f && qmc_last[1] == 0.0f && qmc_last[2] == 0.0f) {
		qmc_last[0] = nv[0]; qmc_last[1] = nv[1]; qmc_last[2] = nv[2];
	} else {
		for (int i = 0; i < 3; i++)
			qmc_last[i] += alpha * (nv[i] - qmc_last[i]);
	}

	d->mx = qmc_last[0]; d->my = qmc_last[1]; d->mz = qmc_last[2];
}

/* ==================== Sensor thread ==================== */
static ImuData latest = {0};
static bool data_ready = false;
static K_MUTEX_DEFINE(dtqsys_mutex);

#define GYRO_BIAS_SAMPLES 200

static void calibrate_gyro_bias(void)
{
	float sum[3] = {0.0f};
	int count = 0;
	int64_t next = k_uptime_get() + 10;

	while (count < GYRO_BIAS_SAMPLES) {
		ImuData d = {0};
		if (icm45686_read_valid(&d)) {
			sum[0] += d.gx;   /* float += float: OK */
			sum[1] += d.gy;
			sum[2] += d.gz;
			count++;
		}
		int64_t delay = next - k_uptime_get();
		if (delay > 0) k_sleep(K_MSEC((int32_t)delay));
		next += 10;
	}

	gyro_bias[0] = sum[0] / GYRO_BIAS_SAMPLES;
	gyro_bias[1] = sum[1] / GYRO_BIAS_SAMPLES;
	gyro_bias[2] = sum[2] / GYRO_BIAS_SAMPLES;
	printk("Gyro bias: gx=%.4f gy=%.4f gz=%.4f rad/s\n",
	       (double)gyro_bias[0], (double)gyro_bias[1], (double)gyro_bias[2]);
}

static void dtqsys_thread(void *p1, void *p2, void *p3)
{
	ARG_UNUSED(p1); ARG_UNUSED(p2); ARG_UNUSED(p3);

	k_sleep(K_MSEC(4000));

	i2c_dev = DEVICE_DT_GET(DT_NODELABEL(i2c0));
	if (!device_is_ready(i2c_dev)) {
		printk("I2C0 not ready! Проверь app.overlay\n");
		return;
	}

	bool icm_ok = false;
	for (int attempt = 1; !icm_ok; attempt++) {
		icm_ok = icm45686_init();
		if (!icm_ok) {
			printk("ICM init fail (попытка %d), повтор через 2с\n", attempt);
			k_sleep(K_MSEC(2000));
		}
	}

	bool qmc_ok = qmc6309_init();
	printk("DTQSYS: ICM=1 QMC=%d — калибровка гироскопа (держи плату неподвижно)...\n", qmc_ok);
	calibrate_gyro_bias();
	printk("DTQSYS ready\n");

	int64_t next_tick = k_uptime_get() + 10;

	while (1) {
		ImuData d = {0};
		if (icm45686_read_valid(&d)) {
			if (qmc_ok) qmc6309_update(&d);
			k_mutex_lock(&dtqsys_mutex, K_FOREVER);
			latest = d;
			data_ready = true;
			k_mutex_unlock(&dtqsys_mutex);
		}

		int64_t delay = next_tick - k_uptime_get();
		if (delay > 0) k_sleep(K_MSEC((int32_t)delay));
		next_tick += 10;
	}
}

K_THREAD_DEFINE(dtqsys_tid, 2048, dtqsys_thread, NULL, NULL, NULL, 5, 0, 0);

/* ==================== IMU driver registration ==================== */
static bool dtqsys_get_data(ImuData *out)
{
	k_mutex_lock(&dtqsys_mutex, K_FOREVER);
	bool ready = data_ready;
	if (ready) {
		*out = latest;
		data_ready = false;
	}
	k_mutex_unlock(&dtqsys_mutex);
	return ready;
}

static const ImuDriverOps dtqsys_driver = {
	.init = NULL,
	.get_data = dtqsys_get_data,
};

static int dtqsys_register(void)
{
	imu_register_driver(&dtqsys_driver);
	return 0;
}

SYS_INIT(dtqsys_register, APPLICATION, CONFIG_APPLICATION_INIT_PRIORITY);
```

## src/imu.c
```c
#include "imu.h"
#include "imu_driver.h"

static const ImuDriverOps *active_driver;

void imu_register_driver(const ImuDriverOps *ops)
{
	active_driver = ops;
}

void imu_init(void)
{
	if (active_driver && active_driver->init) {
		active_driver->init();
	}
}

bool imu_get_data(ImuData *out)
{
	if (!active_driver || !active_driver->get_data) {
		return false;
	}
	return active_driver->get_data(out);
}
```

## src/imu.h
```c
#pragma once
#include <stdbool.h>
#include <stdint.h>

typedef struct {
    float gx, gy, gz;
    float ax, ay, az;
    float mx, my, mz;
    uint32_t timestamp_us;
} ImuData;

void imu_init(void);
bool imu_get_data(ImuData *out);
```

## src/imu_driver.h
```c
#pragma once
#include "imu.h"

typedef struct {
    void (*init)(void);
    bool (*get_data)(ImuData *out);
} ImuDriverOps;

void imu_register_driver(const ImuDriverOps *ops);
```

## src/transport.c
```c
#include <zephyr/kernel.h>
#include <zephyr/usb/usb_device.h>
#include <zephyr/drivers/gpio.h>
#include <zephyr/sys/reboot.h>
#include <zephyr/shell/shell.h>
#include <hal/nrf_power.h>
#include "transport.h"

#define DFU_MAGIC_UF2 0x57

static const struct gpio_dt_spec led = GPIO_DT_SPEC_GET(DT_ALIAS(led0), gpios);
static volatile int usb_state;

static void blink(int n, int ms)
{
	for (int i = 0; i < n; i++) {
		gpio_pin_set_dt(&led, 1);
		k_sleep(K_MSEC(ms));
		gpio_pin_set_dt(&led, 0);
		k_sleep(K_MSEC(ms));
	}
	k_sleep(K_MSEC(500));
}

static void usb_cb(enum usb_dc_status_code status, const uint8_t *param)
{
	usb_state = (int)status;
}

static int cmd_dfu(const struct shell *sh, size_t argc, char **argv)
{
	shell_print(sh, "Entering UF2 bootloader...");
	k_sleep(K_MSEC(100));
	nrf_power_gpregret_set(NRF_POWER, 0, DFU_MAGIC_UF2);
	sys_reboot(SYS_REBOOT_COLD);
	return 0;
}

SHELL_CMD_REGISTER(dfu, NULL, "Reboot into UF2 bootloader", cmd_dfu);

int transport_init(void)
{
	gpio_pin_configure_dt(&led, GPIO_OUTPUT_INACTIVE);
	blink(1, 300);

	int ret = usb_enable(usb_cb);
	if (ret != 0) {
		blink(10, 100);
		return ret;
	}
	blink(2, 300);

	for (int i = 0; i < 100; i++) {
		if (usb_state == USB_DC_CONFIGURED) break;
		k_sleep(K_MSEC(100));
	}
	blink((usb_state == USB_DC_CONFIGURED) ? 3 : 5, 300);

	return 0;
}
```

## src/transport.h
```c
#ifndef TRANSPORT_H
#define TRANSPORT_H

int transport_init(void);

#endif /* TRANSPORT_H */
```
